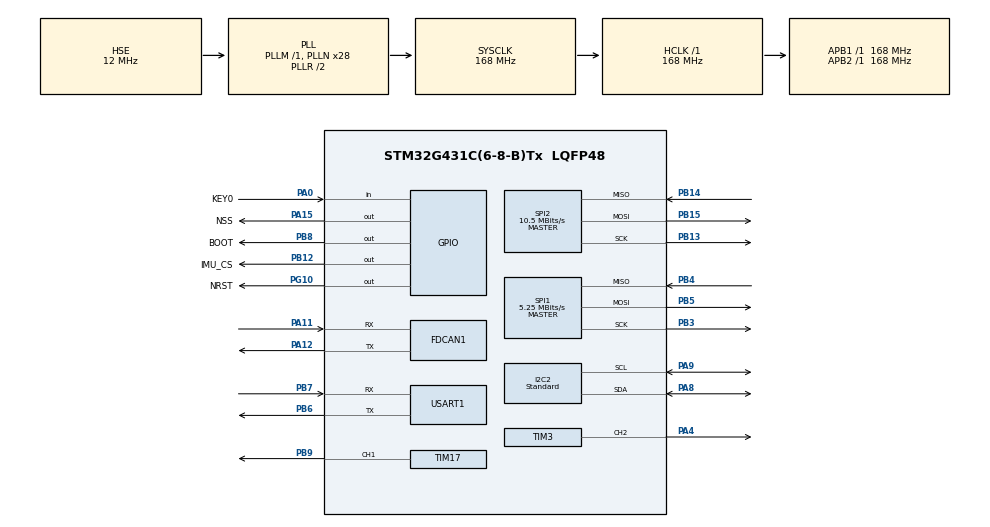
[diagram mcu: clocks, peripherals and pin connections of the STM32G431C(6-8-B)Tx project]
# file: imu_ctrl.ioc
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Dma.Request0=TIM3_CH2
Dma.Request1=USART1_TX
Dma.Request2=USART1_RX
Dma.TIM3_CH2.0.Direction=DMA_MEMORY_TO_PERIPH
Dma.TIM3_CH2.0.EventEnable=DISABLE
Dma.TIM3_CH2.0.Instance=DMA2_Channel2
Dma.TIM3_CH2.0.MemDataAlignment=DMA_MDATAALIGN_HALFWORD
Dma.TIM3_CH2.0.MemInc=DMA_MINC_ENABLE
Dma.TIM3_CH2.0.Mode=DMA_CIRCULAR
Dma.TIM3_CH2.0.PeriphDataAlignment=DMA_PDATAALIGN_HALFWORD
Dma.TIM3_CH2.0.PeriphInc=DMA_PINC_DISABLE
Dma.TIM3_CH2.0.Polarity=HAL_DMAMUX_REQ_GEN_RISING
Dma.TIM3_CH2.0.Priority=DMA_PRIORITY_MEDIUM
Dma.TIM3_CH2.0.RequestNumber=1
Dma.TIM3_CH2.0.SignalID=NONE
Dma.TIM3_CH2.0.SyncEnable=DISABLE
Dma.TIM3_CH2.0.SyncPolarity=HAL_DMAMUX_SYNC_NO_EVENT
Dma.TIM3_CH2.0.SyncRequestNumber=1
Dma.TIM3_CH2.0.SyncSignalID=NONE
Dma.USART1_RX.2.Direction=DMA_PERIPH_TO_MEMORY
Dma.USART1_RX.2.EventEnable=DISABLE
Dma.USART1_RX.2.Instance=DMA1_Channel2
Dma.USART1_RX.2.MemDataAlignment=DMA_MDATAALIGN_BYTE
Dma.USART1_RX.2.MemInc=DMA_MINC_ENABLE
Dma.USART1_RX.2.Mode=DMA_CIRCULAR
Dma.USART1_RX.2.PeriphDataAlignment=DMA_PDATAALIGN_BYTE
Dma.USART1_RX.2.PeriphInc=DMA_PINC_DISABLE
Dma.USART1_RX.2.Polarity=HAL_DMAMUX_REQ_GEN_RISING
Dma.USART1_RX.2.Priority=DMA_PRIORITY_MEDIUM
Dma.USART1_RX.2.RequestNumber=1
Dma.USART1_RX.2.SignalID=NONE
Dma.USART1_RX.2.SyncEnable=DISABLE
Dma.USART1_RX.2.SyncPolarity=HAL_DMAMUX_SYNC_NO_EVENT
Dma.USART1_RX.2.SyncRequestNumber=1
Dma.USART1_RX.2.SyncSignalID=NONE
Dma.USART1_TX.1.Direction=DMA_MEMORY_TO_PERIPH
Dma.USART1_TX.1.EventEnable=DISABLE
Dma.USART1_TX.1.Instance=DMA1_Channel1
Dma.USART1_TX.1.MemDataAlignment=DMA_MDATAALIGN_BYTE
Dma.USART1_TX.1.MemInc=DMA_MINC_ENABLE
Dma.USART1_TX.1.Mode=DMA_NORMAL
Dma.USART1_TX.1.PeriphDataAlignment=DMA_PDATAALIGN_BYTE
Dma.USART1_TX.1.PeriphInc=DMA_PINC_DISABLE
Dma.USART1_TX.1.Polarity=HAL_DMAMUX_REQ_GEN_RISING
Dma.USART1_TX.1.Priority=DMA_PRIORITY_MEDIUM
Dma.USART1_TX.1.RequestNumber=1
Dma.USART1_TX.1.SignalID=NONE
Dma.USART1_TX.1.SyncEnable=DISABLE
Dma.USART1_TX.1.SyncPolarity=HAL_DMAMUX_SYNC_NO_EVENT
Dma.USART1_TX.1.SyncRequestNumber=1
Dma.USART1_TX.1.SyncSignalID=NONE
FDCAN1.AutoRetransmission=DISABLE
FDCAN1.CalculateBaudRateNominal=1000000
FDCAN1.CalculateTimeBitNominal=1000
FDCAN1.CalculateTimeQuantumNominal=47.61904761904762
FDCAN1.ClockDivider=FDCAN_CLOCK_DIV2
FDCAN1.DataPrescaler=5
FDCAN1.DataTimeSeg1=8
FDCAN1.DataTimeSeg2=8
FDCAN1.ExtFiltersNbr=0
FDCAN1.FrameFormat=FDCAN_FRAME_FD_BRS
FDCAN1.NominalPrescaler=4
FDCAN1.NominalTimeSeg1=8
FDCAN1.NominalTimeSeg2=12
FDCAN1.ProtocolException=DISABLE
FDCAN1.StdFiltersNbr=0
FDCAN1.TransmitPause=DISABLE
FREERTOS.Tasks01=NormalTask,24,128,StartNormalTask,As weak,NULL,Static,NormalTaskBuffer,NormalTaskControlBlock;DebugTask,8,256,StartDebugTask,As weak,NULL,Static,DebugTaskBuffer,DebugTaskControlBlock;CanCommTask,40,256,StartCanCommTask,As weak,NULL,Static,CanCommTaskBuffer,CanCommTaskControlBlock;CaclulateTask,32,256,StartCaculateTask,As weak,NULL,Static,CaclulateTaskBuffer,CaclulateTaskControlBlock
FREERTOS.configENABLE_FPU=1
I2C2.I2C_Speed_Mode=I2C_Standard
I2C2.Timing=0x50916E9F
Mcu.Family=STM32G4
Mcu.Name=STM32G431C(6-8-B)Tx
Mcu.Package=LQFP48
NVIC.DMA1_Channel1_IRQn=true\:5\:0\:false\:false\:true\:true\:false\:true\:true
NVIC.DMA1_Channel2_IRQn=true\:5\:0\:false\:false\:true\:true\:false\:true\:true
NVIC.DMA2_Channel2_IRQn=true\:15\:0\:true\:false\:true\:true\:false\:true\:true
NVIC.FDCAN1_IT0_IRQn=true\:5\:0\:true\:false\:true\:true\:true\:true\:true
NVIC.PriorityGroup=NVIC_PRIORITYGROUP_4
NVIC.TIM7_IRQn=true\:5\:0\:false\:false\:true\:true\:true\:true\:true
NVIC.USART1_IRQn=true\:5\:0\:false\:false\:true\:true\:true\:true\:true
PA0.GPIO_Label=KEY0
PA0.GPIO_PuPd=GPIO_PULLUP
PA0.Signal=GPIO_Input
PA11.GPIO_PuPd=GPIO_PULLDOWN
PA11.GPIO_Speed=GPIO_SPEED_FREQ_MEDIUM
PA11.Mode=FDCAN_Activate
PA11.Signal=FDCAN1_RX
PA12.GPIO_PuPd=GPIO_PULLDOWN
PA12.GPIO_Speed=GPIO_SPEED_FREQ_MEDIUM
PA12.Mode=FDCAN_Activate
PA12.Signal=FDCAN1_TX
PA13.Mode=Serial_Wire
PA13.Signal=SYS_JTMS-SWDIO
PA14.Mode=Serial_Wire
PA14.Signal=SYS_JTCK-SWCLK
PA15.GPIO_Label=NSS
PA15.GPIO_PuPd=GPIO_PULLUP
PA15.GPIO_Speed=GPIO_SPEED_FREQ_VERY_HIGH
PA15.Signal=GPIO_Output
PA4.GPIO_ModeDefaultPP=GPIO_MODE_AF_PP
PA4.GPIO_PuPd=GPIO_PULLDOWN
PA4.GPIO_Speed=GPIO_SPEED_FREQ_MEDIUM
PA4.Signal=S_TIM3_CH2
PA8.GPIO_Pu=GPIO_NOPULL
PA8.Mode=I2C
PA8.Signal=I2C2_SDA
PA9.GPIO_Mode=GPIO_MODE_AF_OD
PA9.Mode=I2C
PA9.Signal=I2C2_SCL
PB12.GPIO_Label=IMU_CS
PB12.GPIO_PuPd=GPIO_PULLUP
PB12.GPIO_Speed=GPIO_SPEED_FREQ_MEDIUM
PB12.PinState=GPIO_PIN_RESET
PB12.Signal=GPIO_Output
PB13.GPIO_PuPd=GPIO_PULLDOWN
PB13.GPIO_Speed=GPIO_SPEED_FREQ_MEDIUM
PB13.Mode=Full_Duplex_Master
PB13.Signal=SPI2_SCK
PB14.GPIO_PuPd=GPIO_PULLDOWN
PB14.GPIO_Speed=GPIO_SPEED_FREQ_MEDIUM
PB14.Mode=Full_Duplex_Master
PB14.Signal=SPI2_MISO
PB15.GPIO_PuPd=GPIO_PULLDOWN
PB15.GPIO_Speed=GPIO_SPEED_FREQ_MEDIUM
PB15.Mode=Full_Duplex_Master
PB15.Signal=SPI2_MOSI
PB3.GPIO_PuPd=GPIO_PULLDOWN
PB3.GPIO_Speed=GPIO_SPEED_FREQ_VERY_HIGH
PB3.Mode=Full_Duplex_Master
PB3.Signal=SPI1_SCK
PB4.GPIO_PuPd=GPIO_PULLDOWN
PB4.GPIO_Speed=GPIO_SPEED_FREQ_VERY_HIGH
PB4.Mode=Full_Duplex_Master
PB4.Signal=SPI1_MISO
PB5.GPIO_PuPd=GPIO_PULLDOWN
PB5.GPIO_Speed=GPIO_SPEED_FREQ_VERY_HIGH
PB5.Mode=Full_Duplex_Master
PB5.Signal=SPI1_MOSI
PB6.Mode=Asynchronous
PB6.Signal=USART1_TX
PB7.Mode=Asynchronous
PB7.Signal=USART1_RX
PB8-BOOT0.GPIO_Label=BOOT
PB8-BOOT0.Signal=GPIO_Output
PB9.Signal=S_TIM17_CH1
PF0-OSC_IN.Mode=HSE-External-Clock-Source
PF0-OSC_IN.Signal=RCC_OSC_IN
PG10-NRST.GPIO_Label=NRST
PG10-NRST.Signal=GPIO_Output
ProjectManager.HeapSize=0x400
ProjectManager.StackSize=0x800
ProjectManager.TargetToolchain=CMake
RCC.ADC12Freq_Value=168000000
RCC.AHBFreq_Value=168000000
RCC.APB1Freq_Value=168000000
RCC.APB1TimFreq_Value=168000000
RCC.APB2Freq_Value=168000000
RCC.APB2TimFreq_Value=168000000
RCC.CortexFreq_Value=168000000
RCC.EXTERNAL_CLOCK_VALUE=12288000
RCC.FDCANCLockSelection=RCC_FDCANCLKSOURCE_PLL
RCC.HCLKFreq_Value=168000000
RCC.HSE_VALUE=12000000
RCC.HSI48_VALUE=48000000
RCC.HSI_VALUE=16000000
RCC.LSE_VALUE=32768
RCC.PLLN=28
RCC.PLLSourceVirtual=RCC_PLLSOURCE_HSE
RCC.SYSCLKFreq_VALUE=168000000
RCC.SYSCLKSource=RCC_SYSCLKSOURCE_PLLCLK
RCC.USART3CLockSelection=RCC_USART3CLKSOURCE_SYSCLK
RCC.USBFreq_Value=168000000
RCC.VCOOutputFreq_Value=336000000
SH.S_TIM17_CH1.0=TIM17_CH1,PWM Generation1 CH1
SH.S_TIM3_CH2.0=TIM3_CH2,PWM Generation2 CH2
SPI1.BaudRatePrescaler=SPI_BAUDRATEPRESCALER_32
SPI1.CLKPhase=SPI_PHASE_2EDGE
SPI1.CalculateBaudRate=5.25 MBits/s
SPI1.DataSize=SPI_DATASIZE_16BIT
SPI1.Direction=SPI_DIRECTION_2LINES
SPI1.Mode=SPI_MODE_MASTER
SPI1.VirtualType=VM_MASTER
SPI2.BaudRatePrescaler=SPI_BAUDRATEPRESCALER_16
SPI2.CLKPhase=SPI_PHASE_1EDGE
SPI2.CalculateBaudRate=10.5 MBits/s
SPI2.DataSize=SPI_DATASIZE_8BIT
SPI2.Direction=SPI_DIRECTION_2LINES
SPI2.Mode=SPI_MODE_MASTER
SPI2.VirtualType=VM_MASTER
TIM17.Channel=TIM_CHANNEL_1
TIM17.PeriodNoDither=999
TIM17.Prescaler=167
TIM3.Channel-PWM\ Generation2\ CH2=TIM_CHANNEL_2
TIM3.PeriodNoDither=106
TIM3.Prescaler=1
TIM7.AutoReloadPreload=TIM_AUTORELOAD_PRELOAD_ENABLE
TIM7.PeriodNoDither=999
TIM7.Prescaler=169
USART1.VirtualMode-Asynchronous=VM_ASYNC
VP_FREERTOS_VS_CMSIS_V2.Mode=CMSIS_V2
VP_SYS_VS_DBSignals.Mode=DisableDeadBatterySignals
VP_TIM17_VS_ClockSourceINT.Mode=Enable_Timer
VP_TIM3_VS_ClockSourceINT.Mode=Internal
VP_TIM7_VS_ClockSourceINT.Mode=Enable_Timer
board=custom

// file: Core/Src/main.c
/* USER CODE BEGIN Header */
/**
  ******************************************************************************
  * @file           : main.c
  * @brief          : Main program body
  ******************************************************************************
  * @attention
  *
  * Copyright (c) 2025 STMicroelectronics.
  * All rights reserved.
  *
  * This software is licensed under terms that can be found in the LICENSE file
  * in the root directory of this software component.
  * If no LICENSE file comes with this software, it is provided AS-IS.
  *
  ******************************************************************************
  */
/* USER CODE END Header */
#include "main.h"
#include "cmsis_os.h"
#include "dma.h"
#include "fdcan.h"
#include "i2c.h"
#include "spi.h"
#include "tim.h"
#include "usart.h"
#include "gpio.h"

/* USER CODE BEGIN Includes */
#include "app.h"
/* USER CODE END Includes */

void SystemClock_Config(void);
void MX_FREERTOS_Init(void);

int main(void)
{

  /* MCU Configuration--------------------------------------------------------*/

  /* Reset of all peripherals, Initializes the Flash interface and the Systick. */
  HAL_Init();

  /* Configure the system clock */
  SystemClock_Config();

  /* Initialize all configured peripherals */
  MX_GPIO_Init();
  MX_DMA_Init();
  MX_FDCAN1_Init();
  MX_USART1_UART_Init();
  MX_SPI1_Init();
  MX_TIM3_Init();
  MX_I2C2_Init();
  MX_SPI2_Init();
  MX_TIM7_Init();
  MX_TIM17_Init();
  /* USER CODE BEGIN 2 */
  AppInit();
  /* USER CODE END 2 */

  /* Init scheduler */
  osKernelInitialize();

  /* Call init function for freertos objects (in cmsis_os2.c) */
  MX_FREERTOS_Init();

  /* Start scheduler */
  osKernelStart();

  /* We should never get here as control is now taken by the scheduler */

  /* Infinite loop */
  while (1)
  {

    /* USER CODE BEGIN 3 */
    AppRunning();
  }
  /* USER CODE END 3 */
}

void SystemClock_Config(void)
{
  RCC_OscInitTypeDef RCC_OscInitStruct = {0};
  RCC_ClkInitTypeDef RCC_ClkInitStruct = {0};

  /** Configure the main internal regulator output voltage
  */
  HAL_PWREx_ControlVoltageScaling(PWR_REGULATOR_VOLTAGE_SCALE1_BOOST);

  /** Initializes the RCC Oscillators according to the specified parameters
  * in the RCC_OscInitTypeDef structure.
  */
  RCC_OscInitStruct.OscillatorType = RCC_OSCILLATORTYPE_HSE;
  RCC_OscInitStruct.HSEState = RCC_HSE_BYPASS;
  RCC_OscInitStruct.PLL.PLLState = RCC_PLL_ON;
  RCC_OscInitStruct.PLL.PLLSource = RCC_PLLSOURCE_HSE;
  RCC_OscInitStruct.PLL.PLLM = RCC_PLLM_DIV1;
  RCC_OscInitStruct.PLL.PLLN = 28;
  RCC_OscInitStruct.PLL.PLLP = RCC_PLLP_DIV2;
  RCC_OscInitStruct.PLL.PLLQ = RCC_PLLQ_DIV2;
  RCC_OscInitStruct.PLL.PLLR = RCC_PLLR_DIV2;
  if (HAL_RCC_OscConfig(&RCC_OscInitStruct) != HAL_OK)
  {
    Error_Handler();
  }

  /** Initializes the CPU, AHB and APB buses clocks
  */
  RCC_ClkInitStruct.ClockType = RCC_CLOCKTYPE_HCLK|RCC_CLOCKTYPE_SYSCLK
                              |RCC_CLOCKTYPE_PCLK1|RCC_CLOCKTYPE_PCLK2;
  RCC_ClkInitStruct.SYSCLKSource = RCC_SYSCLKSOURCE_PLLCLK;
  RCC_ClkInitStruct.AHBCLKDivider = RCC_SYSCLK_DIV1;
  RCC_ClkInitStruct.APB1CLKDivider = RCC_HCLK_DIV1;
  RCC_ClkInitStruct.APB2CLKDivider = RCC_HCLK_DIV1;

  if (HAL_RCC_ClockConfig(&RCC_ClkInitStruct, FLASH_LATENCY_4) != HAL_OK)
  {
    Error_Handler();
  }
}

void Error_Handler(void)
{
  __disable_irq();
  while (1)
  {
  }
}

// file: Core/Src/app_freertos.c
/* USER CODE BEGIN Header */
/**
  ******************************************************************************
  * File Name          : app_freertos.c
  * Description        : Code for freertos applications
  ******************************************************************************
  * @attention
  *
  * Copyright (c) 2025 STMicroelectronics.
  * All rights reserved.
  *
  * This software is licensed under terms that can be found in the LICENSE file
  * in the root directory of this software component.
  * If no LICENSE file comes with this software, it is provided AS-IS.
  *
  ******************************************************************************
  */
/* USER CODE END Header */

#include "FreeRTOS.h"
#include "task.h"
#include "main.h"
#include "cmsis_os.h"

typedef StaticTask_t osStaticThreadDef_t;

/* Definitions for NormalTask */
osThreadId_t NormalTaskHandle;
uint32_t NormalTaskBuffer[ 128 ];
osStaticThreadDef_t NormalTaskControlBlock;
const osThreadAttr_t NormalTask_attributes = {
  .name = "NormalTask",
  .stack_mem = &NormalTaskBuffer[0],
  .stack_size = sizeof(NormalTaskBuffer),
  .cb_mem = &NormalTaskControlBlock,
  .cb_size = sizeof(NormalTaskControlBlock),
  .priority = (osPriority_t) osPriorityNormal,
};
/* Definitions for DebugTask */
osThreadId_t DebugTaskHandle;
uint32_t DebugTaskBuffer[ 256 ];
osStaticThreadDef_t DebugTaskControlBlock;
const osThreadAttr_t DebugTask_attributes = {
  .name = "DebugTask",
  .stack_mem = &DebugTaskBuffer[0],
  .stack_size = sizeof(DebugTaskBuffer),
  .cb_mem = &DebugTaskControlBlock,
  .cb_size = sizeof(DebugTaskControlBlock),
  .priority = (osPriority_t) osPriorityLow,
};
/* Definitions for CanCommTask */
osThreadId_t CanCommTaskHandle;
uint32_t CanCommTaskBuffer[ 256 ];
osStaticThreadDef_t CanCommTaskControlBlock;
const osThreadAttr_t CanCommTask_attributes = {
  .name = "CanCommTask",
  .stack_mem = &CanCommTaskBuffer[0],
  .stack_size = sizeof(CanCommTaskBuffer),
  .cb_mem = &CanCommTaskControlBlock,
  .cb_size = sizeof(CanCommTaskControlBlock),
  .priority = (osPriority_t) osPriorityHigh,
};
/* Definitions for CaclulateTask */
osThreadId_t CaclulateTaskHandle;
uint32_t CaclulateTaskBuffer[ 256 ];
osStaticThreadDef_t CaclulateTaskControlBlock;
const osThreadAttr_t CaclulateTask_attributes = {
  .name = "CaclulateTask",
  .stack_mem = &CaclulateTaskBuffer[0],
  .stack_size = sizeof(CaclulateTaskBuffer),
  .cb_mem = &CaclulateTaskControlBlock,
  .cb_size = sizeof(CaclulateTaskControlBlock),
  .priority = (osPriority_t) osPriorityAboveNormal,
};

void StartNormalTask(void *argument);
void StartDebugTask(void *argument);
void StartCanCommTask(void *argument);
void StartCaculateTask(void *argument);

void MX_FREERTOS_Init(void); /* (MISRA C 2004 rule 8.1) */

void MX_FREERTOS_Init(void) {

  /* Create the thread(s) */
  /* creation of NormalTask */
  NormalTaskHandle = osThreadNew(StartNormalTask, NULL, &NormalTask_attributes);

  /* creation of DebugTask */
  DebugTaskHandle = osThreadNew(StartDebugTask, NULL, &DebugTask_attributes);

  /* creation of CanCommTask */
  CanCommTaskHandle = osThreadNew(StartCanCommTask, NULL, &CanCommTask_attributes);

  /* creation of CaclulateTask */
  CaclulateTaskHandle = osThreadNew(StartCaculateTask, NULL, &CaclulateTask_attributes);

}

__weak void StartNormalTask(void *argument)
{
  for(;;)
  {
    osDelay(1);
  }
}

__weak void StartDebugTask(void *argument)
{
  for(;;)
  {
    osDelay(1);
  }
}

__weak void StartCanCommTask(void *argument)
{
  for(;;)
  {
    osDelay(1);
  }
}

__weak void StartCaculateTask(void *argument)
{
  for(;;)
  {
    osDelay(1);
  }
}
